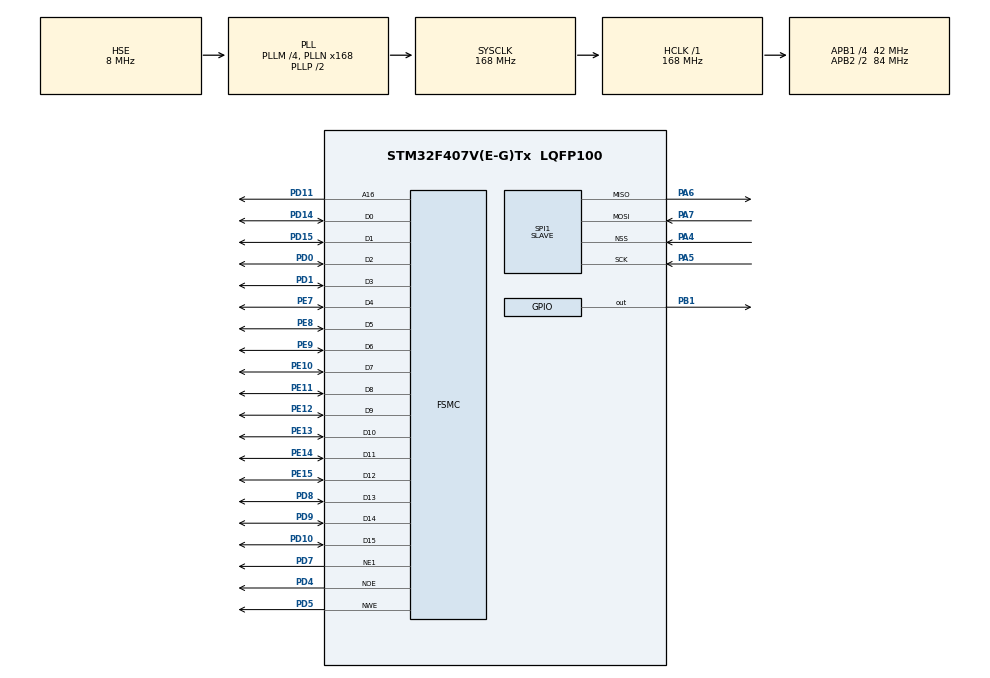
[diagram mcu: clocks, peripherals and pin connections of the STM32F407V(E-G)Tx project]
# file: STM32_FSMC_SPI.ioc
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Dma.Request0=SPI1_RX
Dma.Request1=SPI1_TX
Dma.SPI1_RX.0.Direction=DMA_PERIPH_TO_MEMORY
Dma.SPI1_RX.0.FIFOMode=DMA_FIFOMODE_DISABLE
Dma.SPI1_RX.0.Instance=DMA2_Stream0
Dma.SPI1_RX.0.MemDataAlignment=DMA_MDATAALIGN_BYTE
Dma.SPI1_RX.0.MemInc=DMA_MINC_ENABLE
Dma.SPI1_RX.0.Mode=DMA_CIRCULAR
Dma.SPI1_RX.0.PeriphDataAlignment=DMA_PDATAALIGN_BYTE
Dma.SPI1_RX.0.PeriphInc=DMA_PINC_DISABLE
Dma.SPI1_RX.0.Priority=DMA_PRIORITY_LOW
Dma.SPI1_TX.1.Direction=DMA_MEMORY_TO_PERIPH
Dma.SPI1_TX.1.FIFOMode=DMA_FIFOMODE_DISABLE
Dma.SPI1_TX.1.Instance=DMA2_Stream3
Dma.SPI1_TX.1.MemDataAlignment=DMA_MDATAALIGN_BYTE
Dma.SPI1_TX.1.MemInc=DMA_MINC_ENABLE
Dma.SPI1_TX.1.Mode=DMA_CIRCULAR
Dma.SPI1_TX.1.PeriphDataAlignment=DMA_PDATAALIGN_BYTE
Dma.SPI1_TX.1.PeriphInc=DMA_PINC_DISABLE
Dma.SPI1_TX.1.Priority=DMA_PRIORITY_LOW
FSMC.AddressSetupTime1=1
FSMC.BusTurnAroundDuration1=0
FSMC.DataSetupTime1=5
Mcu.Family=STM32F4
Mcu.Name=STM32F407V(E-G)Tx
Mcu.Package=LQFP100
NVIC.DMA2_Stream0_IRQn=true\:0\:0\:false\:false\:true\:false\:true
NVIC.DMA2_Stream3_IRQn=true\:0\:0\:false\:false\:true\:false\:true
NVIC.PriorityGroup=NVIC_PRIORITYGROUP_4
PA4.Mode=NSS_Signal_Hard_Input
PA4.Signal=SPI1_NSS
PA5.Mode=Full_Duplex_Slave
PA5.Signal=SPI1_SCK
PA6.Mode=Full_Duplex_Slave
PA6.Signal=SPI1_MISO
PA7.Mode=Full_Duplex_Slave
PA7.Signal=SPI1_MOSI
PB1.Signal=GPIO_Output
PD0.Mode=16b-d1
PD0.Signal=FSMC_D2
PD1.Mode=16b-d1
PD1.Signal=FSMC_D3
PD10.Mode=16b-d1
PD10.Signal=FSMC_D15
PD11.Mode=A16_1
PD11.Signal=FSMC_A16
PD13.Signal=FSMC_A18
PD14.Mode=16b-d1
PD14.Signal=FSMC_D0
PD15.Mode=16b-d1
PD15.Signal=FSMC_D1
PD4.Mode=Lcd1
PD4.Signal=FSMC_NOE
PD5.Mode=Lcd1
PD5.Signal=FSMC_NWE
PD7.Mode=NorPsramChipSelect1_1
PD7.Signal=FSMC_NE1
PD8.Mode=16b-d1
PD8.Signal=FSMC_D13
PD9.Mode=16b-d1
PD9.Signal=FSMC_D14
PE10.Mode=16b-d1
PE10.Signal=FSMC_D7
PE11.Mode=16b-d1
PE11.Signal=FSMC_D8
PE12.Mode=16b-d1
PE12.Signal=FSMC_D9
PE13.Mode=16b-d1
PE13.Signal=FSMC_D10
PE14.Mode=16b-d1
PE14.Signal=FSMC_D11
PE15.Mode=16b-d1
PE15.Signal=FSMC_D12
PE7.Mode=16b-d1
PE7.Signal=FSMC_D4
PE8.Mode=16b-d1
PE8.Signal=FSMC_D5
PE9.Mode=16b-d1
PE9.Signal=FSMC_D6
PH0-OSC_IN.Mode=HSE-External-Oscillator
PH0-OSC_IN.Signal=RCC_OSC_IN
PH1-OSC_OUT.Mode=HSE-External-Oscillator
PH1-OSC_OUT.Signal=RCC_OSC_OUT
ProjectManager.HeapSize=0x200
ProjectManager.StackSize=0x400
ProjectManager.TargetToolchain=MDK-ARM V5.27
RCC.48MHZClocksFreq_Value=48000000
RCC.AHBFreq_Value=168000000
RCC.APB1CLKDivider=RCC_HCLK_DIV4
RCC.APB1Freq_Value=42000000
RCC.APB1TimFreq_Value=84000000
RCC.APB2CLKDivider=RCC_HCLK_DIV2
RCC.APB2Freq_Value=84000000
RCC.APB2TimFreq_Value=168000000
RCC.CortexFreq_Value=168000000
RCC.HCLKFreq_Value=168000000
RCC.HSE_VALUE=8000000
RCC.HSI_VALUE=16000000
RCC.LSE_VALUE=32768
RCC.PLLM=4
RCC.PLLN=168
RCC.PLLQ=7
RCC.PLLSourceVirtual=RCC_PLLSOURCE_HSE
RCC.SYSCLKFreq_VALUE=168000000
RCC.SYSCLKSource=RCC_SYSCLKSOURCE_PLLCLK
RCC.VCOOutputFreq_Value=336000000
SPI1.Direction=SPI_DIRECTION_2LINES
SPI1.Mode=SPI_MODE_SLAVE
SPI1.VirtualNSS=VM_NSSHARD
SPI1.VirtualType=VM_SLAVE
board=custom

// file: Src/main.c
/* USER CODE BEGIN Header */
/**
  ******************************************************************************
  * @file           : main.c
  * @brief          : Main program body
  ******************************************************************************
  * @attention
  *
  * <h2><center>&copy; Copyright (c) 2021 STMicroelectronics.
  * All rights reserved.</center></h2>
  *
  * This software component is licensed by ST under BSD 3-Clause license,
  * the "License"; You may not use this file except in compliance with the
  * License. You may obtain a copy of the License at:
  *                        opensource.org/licenses/BSD-3-Clause
  *
  ******************************************************************************
  */
/* USER CODE END Header */

#include "main.h"

/* USER CODE BEGIN Includes */

#include "spi_translater.h"
/* USER CODE END Includes */

SPI_HandleTypeDef hspi1;
DMA_HandleTypeDef hdma_spi1_rx;
DMA_HandleTypeDef hdma_spi1_tx;

SRAM_HandleTypeDef hsram1;

void SystemClock_Config(void);
static void MX_GPIO_Init(void);
static void MX_DMA_Init(void);
static void MX_FSMC_Init(void);
static void MX_SPI1_Init(void);

int main(void)
{

  /* MCU Configuration--------------------------------------------------------*/

  /* Reset of all peripherals, Initializes the Flash interface and the Systick. */
  HAL_Init();

  /* Configure the system clock */
  SystemClock_Config();

  /* Initialize all configured peripherals */
  MX_GPIO_Init();
  MX_DMA_Init();
  MX_FSMC_Init();
  MX_SPI1_Init();
  /* USER CODE BEGIN 2 */

  LCD_BL_ON();
  SPI_Translater_Init();

//  lcdInit();
//  lcdTest();
//
//  HAL_Delay(1000);
//  lcdFillRGB(0x0000);
  /* USER CODE END 2 */

  /* Infinite loop */
  while (1)
  {

  }
}

void SystemClock_Config(void)
{
  RCC_OscInitTypeDef RCC_OscInitStruct = {0};
  RCC_ClkInitTypeDef RCC_ClkInitStruct = {0};

  /** Configure the main internal regulator output voltage
  */
  __HAL_RCC_PWR_CLK_ENABLE();
  __HAL_PWR_VOLTAGESCALING_CONFIG(PWR_REGULATOR_VOLTAGE_SCALE1);
  /** Initializes the CPU, AHB and APB busses clocks
  */
  RCC_OscInitStruct.OscillatorType = RCC_OSCILLATORTYPE_HSE;
  RCC_OscInitStruct.HSEState = RCC_HSE_ON;
  RCC_OscInitStruct.PLL.PLLState = RCC_PLL_ON;
  RCC_OscInitStruct.PLL.PLLSource = RCC_PLLSOURCE_HSE;
  RCC_OscInitStruct.PLL.PLLM = 4;
  RCC_OscInitStruct.PLL.PLLN = 168;
  RCC_OscInitStruct.PLL.PLLP = RCC_PLLP_DIV2;
  RCC_OscInitStruct.PLL.PLLQ = 7;
  if (HAL_RCC_OscConfig(&RCC_OscInitStruct) != HAL_OK)
  {
    Error_Handler();
  }
  /** Initializes the CPU, AHB and APB busses clocks
  */
  RCC_ClkInitStruct.ClockType = RCC_CLOCKTYPE_HCLK|RCC_CLOCKTYPE_SYSCLK
                              |RCC_CLOCKTYPE_PCLK1|RCC_CLOCKTYPE_PCLK2;
  RCC_ClkInitStruct.SYSCLKSource = RCC_SYSCLKSOURCE_PLLCLK;
  RCC_ClkInitStruct.AHBCLKDivider = RCC_SYSCLK_DIV1;
  RCC_ClkInitStruct.APB1CLKDivider = RCC_HCLK_DIV4;
  RCC_ClkInitStruct.APB2CLKDivider = RCC_HCLK_DIV2;

  if (HAL_RCC_ClockConfig(&RCC_ClkInitStruct, FLASH_LATENCY_5) != HAL_OK)
  {
    Error_Handler();
  }
}

static void MX_SPI1_Init(void)
{

  /* SPI1 parameter configuration*/
  hspi1.Instance = SPI1;
  hspi1.Init.Mode = SPI_MODE_SLAVE;
  hspi1.Init.Direction = SPI_DIRECTION_2LINES;
  hspi1.Init.DataSize = SPI_DATASIZE_8BIT;
  hspi1.Init.CLKPolarity = SPI_POLARITY_LOW;
  hspi1.Init.CLKPhase = SPI_PHASE_1EDGE;
  hspi1.Init.NSS = SPI_NSS_HARD_INPUT;
  hspi1.Init.FirstBit = SPI_FIRSTBIT_MSB;
  hspi1.Init.TIMode = SPI_TIMODE_DISABLE;
  hspi1.Init.CRCCalculation = SPI_CRCCALCULATION_DISABLE;
  hspi1.Init.CRCPolynomial = 10;
  if (HAL_SPI_Init(&hspi1) != HAL_OK)
  {
    Error_Handler();
  }

}

static void MX_DMA_Init(void)
{

  /* DMA controller clock enable */
  __HAL_RCC_DMA2_CLK_ENABLE();

  /* DMA interrupt init */
  /* DMA2_Stream0_IRQn interrupt configuration */
  HAL_NVIC_SetPriority(DMA2_Stream0_IRQn, 0, 0);
  HAL_NVIC_EnableIRQ(DMA2_Stream0_IRQn);
  /* DMA2_Stream3_IRQn interrupt configuration */
  HAL_NVIC_SetPriority(DMA2_Stream3_IRQn, 0, 0);
  HAL_NVIC_EnableIRQ(DMA2_Stream3_IRQn);

}

static void MX_GPIO_Init(void)
{
  GPIO_InitTypeDef GPIO_InitStruct = {0};

  /* GPIO Ports Clock Enable */
  __HAL_RCC_GPIOH_CLK_ENABLE();
  __HAL_RCC_GPIOA_CLK_ENABLE();
  __HAL_RCC_GPIOB_CLK_ENABLE();
  __HAL_RCC_GPIOE_CLK_ENABLE();
  __HAL_RCC_GPIOD_CLK_ENABLE();

  /*Configure GPIO pin Output Level */
  HAL_GPIO_WritePin(GPIOB, GPIO_PIN_1, GPIO_PIN_RESET);

  /*Configure GPIO pin : PB1 */
  GPIO_InitStruct.Pin = GPIO_PIN_1;
  GPIO_InitStruct.Mode = GPIO_MODE_OUTPUT_PP;
  GPIO_InitStruct.Pull = GPIO_NOPULL;
  GPIO_InitStruct.Speed = GPIO_SPEED_FREQ_LOW;
  HAL_GPIO_Init(GPIOB, &GPIO_InitStruct);

}

/* FSMC initialization function */
static void MX_FSMC_Init(void)
{

  FSMC_NORSRAM_TimingTypeDef Timing = {0};

  /** Perform the SRAM1 memory initialization sequence
  */
  hsram1.Instance = FSMC_NORSRAM_DEVICE;
  hsram1.Extended = FSMC_NORSRAM_EXTENDED_DEVICE;
  /* hsram1.Init */
  hsram1.Init.NSBank = FSMC_NORSRAM_BANK1;
  hsram1.Init.DataAddressMux = FSMC_DATA_ADDRESS_MUX_DISABLE;
  hsram1.Init.MemoryType = FSMC_MEMORY_TYPE_SRAM;
  hsram1.Init.MemoryDataWidth = FSMC_NORSRAM_MEM_BUS_WIDTH_16;
  hsram1.Init.BurstAccessMode = FSMC_BURST_ACCESS_MODE_DISABLE;
  hsram1.Init.WaitSignalPolarity = FSMC_WAIT_SIGNAL_POLARITY_LOW;
  hsram1.Init.WrapMode = FSMC_WRAP_MODE_DISABLE;
  hsram1.Init.WaitSignalActive = FSMC_WAIT_TIMING_BEFORE_WS;
  hsram1.Init.WriteOperation = FSMC_WRITE_OPERATION_ENABLE;
  hsram1.Init.WaitSignal = FSMC_WAIT_SIGNAL_DISABLE;
  hsram1.Init.ExtendedMode = FSMC_EXTENDED_MODE_DISABLE;
  hsram1.Init.AsynchronousWait = FSMC_ASYNCHRONOUS_WAIT_DISABLE;
  hsram1.Init.WriteBurst = FSMC_WRITE_BURST_DISABLE;
  hsram1.Init.PageSize = FSMC_PAGE_SIZE_NONE;
  /* Timing */
  Timing.AddressSetupTime = 1;
  Timing.AddressHoldTime = 15;
  Timing.DataSetupTime = 5;
  Timing.BusTurnAroundDuration = 0;
  Timing.CLKDivision = 16;
  Timing.DataLatency = 17;
  Timing.AccessMode = FSMC_ACCESS_MODE_A;
  /* ExtTiming */

  if (HAL_SRAM_Init(&hsram1, &Timing, NULL) != HAL_OK)
  {
    Error_Handler( );
  }

}

void Error_Handler(void)
{
}

/************************ (C) COPYRIGHT STMicroelectronics *****END OF FILE****/
